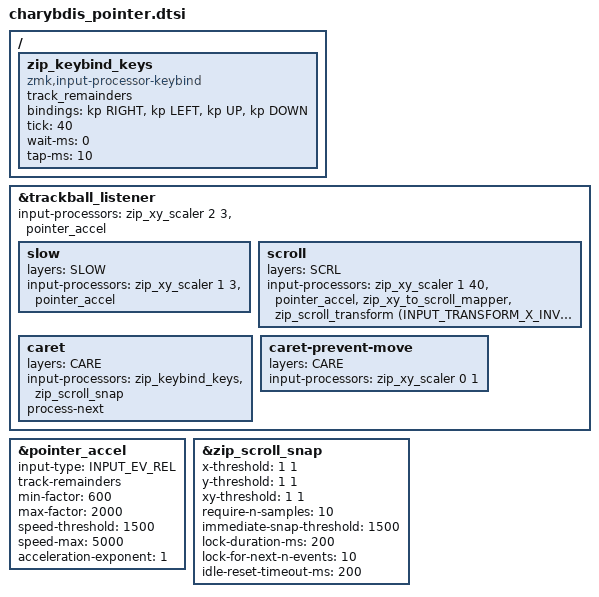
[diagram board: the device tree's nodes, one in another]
#include <input/processors.dtsi>
#include <input/processors/zmk-input-processor-keybind.dtsi>
#include <behaviors/input_gestures_accel.dtsi>
#include <dt-bindings/zmk/input_transform.h>
#include <scroll-snap.dtsi>
#include "includes/layers.h"
#include "zmk-helpers/key-labels/36.h"

&trackball_listener {
    input-processors = <
        &zip_xy_scaler 2 3
        &pointer_accel
    >;

    slow {
        layers = <SLOW>;
        input-processors = <
            &zip_xy_scaler 1 3
            &pointer_accel
        >;
    };

    scroll {
        layers = <SCRL>;
        input-processors = <
            &zip_xy_scaler 1 40
            &pointer_accel
            &zip_xy_to_scroll_mapper
            &zip_scroll_transform (INPUT_TRANSFORM_X_INVERT | INPUT_TRANSFORM_Y_INVERT)
        >;
    };

    caret {
        layers = <CARE>;
        input-processors = <
            &zip_keybind_keys
            &zip_scroll_snap
        >;
        process-next;
    };

    // хак, чтобы на курсор не перемещался на слое CARE
    // https://github.com/zmkfirmware/zmk/issues/2967#issuecomment-2982313146
    caret-prevent-move {
        layers = <CARE>;
        input-processors = <&zip_xy_scaler 0 1>;
    };
};

&pointer_accel {
    input-type = <INPUT_EV_REL>;
    track-remainders;
    min-factor = <600>;
    max-factor = <2000>;
    speed-threshold = <1500>;
    speed-max = <5000>;
    acceleration-exponent = <1>;
};

&zip_scroll_snap {
    x-threshold = <1 1>;
    y-threshold = <1 1>;
    xy-threshold = <1 1>;

    require-n-samples = <10>;
    immediate-snap-threshold = <1500>;
    lock-duration-ms = <200>;
    lock-for-next-n-events = <10>;
    idle-reset-timeout-ms = <200>;
};

/ {
    zip_keybind_keys: zip_keybind_keys {
        compatible = "zmk,input-processor-keybind";
        #input-processor-cells = <0>;
        track_remainders;
        bindings = <&kp RIGHT>,
                   <&kp LEFT>,
                   <&kp UP>,
                   <&kp DOWN>;
        tick = <40>;
        wait-ms = <0>;
        tap-ms = <10>;
    };
};
